# MSS_SPI register map
Vendor: Texas Instruments
Registers are 32-bit, access per field, no defined reset value unless marked. A register's access mark holds for its fields unless they carry their own. Offsets are as the file gives them; [hi:lo] are bit positions; lines under a group give offsets from that group; {n}, {i} and the like mark numbered series.

## MSS_SPI (part 2 of 3)
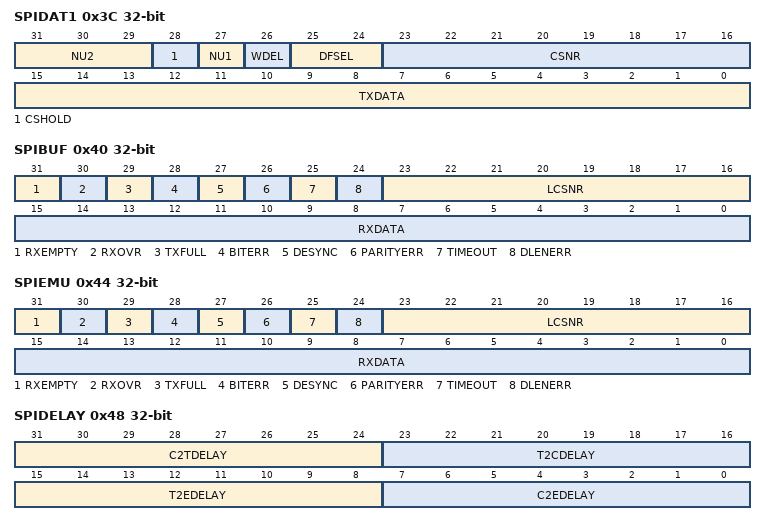
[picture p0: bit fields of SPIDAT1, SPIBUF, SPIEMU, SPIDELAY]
0x3C SPIDAT1 — SPI / MibSPI Transmit Data Register 1 When this register is read, contents of internal buffer register TXBUF which holds the latest written data will be returned.
  [31:29] NU2 ro — Reserved. Reads return ‘0’ and writes have no effect.
  [28] CSHOLD rw — Chip select hold mode. In SPI or compatibility mode MibSPI, the CSHOLD bit is supported in master mode only. In slave mode, this bit is ignored. CSHOLD defines the behavior of the chip select line at the end of a data transfer. 1 =The chip select signal is held active at the end of a transfer until a control field with new data and control information is loaded into SPIDAT1. If the new chip select information equals the previous one, the active chip select signal is extended until the end of transfer with CSHOLD cleared or until the chip select information changes. 0 =The chip select signal is deactivated at the end of a transfer after the T2CDELAY time has passed. If two consecutive transfers are dedicated to the same chip select this chip select signal will be deactivated for atleast 2VCLK cycles before it is activated again.
  [27] NU1 ro — Reserved. Reads return ‘0’ and writes have no effect.
  [26] WDEL rw — Enable the delay counter at the end of the current transaction. WDELAY bit is supported in Master mode only. In Slave mode, this bit will be ignored. 1 = After a transaction, WDELAY of the corresponding data format will be loaded into the delay counter. No transaction will be performed until the WDELAY counter overflows. The SPISCS pins will be de-activated for atleast (WDELAY + 2) * VCLK_Period duration. 0 = No delay will be inserted. However, SPISCS pins will still be de-activated for atleast for 2VCLK cycles if CSHOLD = ‘0’. In SPI or Compatibility mode of MibSPI, the duration for which the SPISCS pin remaining de-activated will also depend upon time taken to supply a new data after completing the shifting operation. If the internal buffer - TXBUF is already full, then the SPISCS will be deasserted for atleast 2 VCLK cycles(if WDEL = ‘0’).
  [25:24] DFSEL rw — DFSEL1 DFSEL0 Description 0 0 Data word format 0 is selected 0 1 Data word format 1 is selected 1 0 Data word format 2 is selected 1 1 Data word format 3 is selected
  [23:16] CSNR rw — Chip select number. CSNR defines the chip select that shall be activated during the data transfer. The value of CSNR[7:0] will be driven on SPISCS[7:0] lines during the transfer. Note: Effect of NUM_CS_PINS generic on CSNR bits. Actual number of bits implemented in CSNR[7:0] will depend upon the NUM_CS_PINS generic set during synthesis. Unimplemented bits will be read-only and will read ‘0’ always. Note: Preselecting a Format Register. Writing to just the Control Field (using byte writes) does not initiate any SPI transfer in Master mode. This feature can be used to setup SPICLK Phase or Polarity before actually starting the transfer by just updating the DFSEL fields in the control field to select the required Phase/Polarity combination.
  [15:0] TXDATA rw — SPI / MibSPI Transmit Data. When written, these bits will be copied to the Shift Register if it is empty. If the Shift Register is not empty, the TXBUF will hold the written values. SPIEN must be set to 1 before this register can be written to. Writing a 0 to the SPIEN register forces the lower 16 bits of the SPIDAT1 register to 0x00. Write to this register ONLY when using the automatic Slave Chip Select feature. See section 3, Operation Modes, on page 14. A write to this register will drive the contents of CSNR[7:0] into the respective pins in SPISCS[7:0] if those are configured as functional pins. When this register is read, contents of internal buffer register TXBUF which holds the latest written data will be returned. Irrespective of the character length, the Transmit data should be right justified before writing to SPIDAT1 register.
0x40 SPIBUF access not given — SPI / MibSPI Receive Buffer Register
  [31] RXEMPTY — Receive data buffer empty. When host reads the SPIBUF field or the whole SPIBUF register this will automatically set the RXEMPTY flag. When a data transfer is completed, the received data is copied into SPIBUF, the RXEMPTY flag is cleared. 1 =No data received since last reading of SPIBUF register. 0 =A new Data is received and copied into SPIBUF field. This flag gets set to ‘1’ under following conditions: oReading RXDATA portion of the SPIBUF register. oWriting ‘1’ to clear the RXINTFLG bit in SPIFLG register. Write-Clearing the RXINTFLG bit before reading the SPIBUF indicates the received data is being ignored. Conversely, RXINTFLG can be cleared by reading the RXDATA portion of the SPIBUF register. So, reading the full of SPIBUF register itself clears the Receiver Full Interrupt Flag.
  [30] RXOVR — Receive data buffer overrun. When a data transfer is completed and the received data is copied into the RXBUF while it is already full, RXOVR is set. Refer to Figure 1 for a view of internal logic diagram. An Overrun always occurs to the RXBUF, and SPIBUF contents never get Overwritten until after it is read by the VBUSP Master. If enabled, RXOVRN interrupt gets generated when RXBUF is Overwritten, and reading SPIFLG or SPIVECTx register shows the RXOVRN condition. However, two read operations to the SPIBUF register are required to reach the Overrun buffer. 1 =A receive data overrun condition occurred since last time reading the data field. 0 =No receive data overrun condition occurred since last time reading the data field. This bit is cleared to ‘0’ under the following conditions: o RXDATA portion of the SPIBUF register is read. o OVRNINTFLG bit in SPIFLG register is write-cleared. When an Overrun occurs, the SPIBUF contents will not be overwritten. Only the RXBUF contents are overwritten. When the SPIBUF is read out , the RXBUF contents get copied to the SPIBUF if RXBUF is full. So, the first data read out will be intact when an Overrun occurs. Note: A special condition under which RXOVR flag gets set. If both SPIBUF & RXBUF are already full and while another buffer receive is underway, if any errors like TIMEOUT, BITERR & DLEN_ERR occur, then RXOVR in RXBUF & SPIFLG registers will be set to indicate that the status flags are getting overwritten by the new transfer. This overrun should be treated like a normal Receiver Overrun.
  [29] TXFULL ro — Transmit data buffer full. This flag is a read-only flag. Writing into SPIDAT0 or SPIDAT1 field while TX Shift Register is full will automatically set the TXFULL flag. Once the data is copied to the Shift Register the TXFULL flag will be cleared. Writing to SPIDAT0/SPIDAT1 register when both TXBUF & the TX Shift Register are empty does not set the TXFULL flag. 1 =Transmit buffer is full, SPIDAT0/SPIDAT1 is not ready to accept a new data. 0 =Transmit buffer is empty, SPIDAT0/SPIDAT1 is ready to accept a new data.
  [28] BITERR — Mismatch of internal transmit data and transmitted data. 1 =A bit error occurred. The SPI / MibSPI samples the signal of the transmit pin (master: SIMO, slave: SOMI) at the receive point (half clock cycle after transmit point). If the sampled value differs from the transmitted value a bit error is detected and the flag BITERR is set. A possible reason for a bit error can be noise, a to high bit rate / capacitive load or another master/slave trying to transmit at the same time. 0 =No bit error occurred. This flag is cleared to ‘0’ when RXDATA portion of the SPIBUF register is read.
  [27] DESYNC — De-synchronization of slave device. De-synchronization monitor is active in master mode only. 1 =A slave device is de-synchronized. The master monitors the ENA signal coming from the slave device and sets the DESYNC flag if ENA is deactivated before the last reception point or after the last bit is transmitted plus tT2EDELAY (see Section 8.21). If DESYNCENA is set an interrupt is asserted. De-synchronization can occur if a slave device misses a clock edge coming from the master. 0 =No slave de-synchronization detected. This bit is valid in Master mode only. This flag is cleared to ‘0’ when RXDATA portion of the SPIBUF register is read. Note: Possible inconsistency of Desync flag in SPI/Compatibility mode MibSPI Due to the nature of this Error, under some circumstances it is possible for Desync error detected for the previous buffer to be visible in the current buffer. This is due to the fact that Receive Completion flag/interrupt will be generated when the buffer transfer is completed. But Desync will be detected after the buffer transfer is completed. So, if VBUS master reads the received data quickly when an RXINT is detected, then the status flag may not reflect the correct Desync condition. This inconsistency in Desync flag is valid only in SPI or Compatibility mode of MibSPI. In Multibuffer mode, Desync flag is always guaranteed to be for the current buffer.
  [26] PARITYERR — Calculated parity differs from received parity bit. 1 =A parity error occurred. If the parity generator is enabled (can be selected individually for each buffer) an even or odd parity bit is added at the end of a data word (see Section 8.23). During reception of the data word the parity generator calculates the reference parity and compares it to the received parity bit. In the event of a mismatch the PARITYERR flag is set. 0 =No parity error detected. This flag is cleared to ‘0’ when RXDATA portion of the SPIBUF register is read.
  [25] TIMEOUT — Time-out due to non-activation of ENA pin. 1 =An ENA signal time-out occurred. The SPI / MibSPI generates a time-out because the slave hasn’t responded in time by activating the ENA signal after the chip select signal has been activated. If a time-out condition is detected the corresponding chip select is deactivated immediately and the TIMEOUT flag is set. In addition the TIMOUT flag in the status field of the corresponding buffer and in the SPIFLG register is set. 0 =No ENA-pin time-out occurred. This flag is cleared to ‘0’ when RXDATA portion of the SPIBUF register is read. This bit is valid in Master mode only.
  [24] DLENERR — Data Length Error flag. 1 = A Data Length Error has occured. 0 = No Data Length Error has occured. This flag is cleared to ‘0’ when RXDATA portion of the SPIBUF register is read.
  [23:16] LCSNR ro — Last Chip select number. LCSNR in the status field is a copy of CSNR in the corresponding control field. It defines the chip select that has been activated during the last data transfer from the corresponding buffer. This is the copy of CSNR bits from SPIDAT1 latched at the end of a transfer. Note: Effect of NUM_CS_PINS generic on LCSNR bits. Actual number of bits implemented in LCSNR[7:0] will depend upon the NUM_CS_PINS generic set during synthesis. Unimplemented bits will read ‘0’ always
  [15:0] RXDATA ro — SPI Receive Data. This is the received data, transferred from the Receive Shift-Register at the end of a transfer completion. Irrespective of the programmed character length & the direction of shifting, the received data is stored right-justified in the register.
0x44 SPIEMU ro — SPI / MibSPI Emulation Register Note: All the fields ot SPIEMU register are Read-Only. Read operation on this register under any mode will not have any impact on the status of this or any other registers.
  [31] RXEMPTY — Receive data buffer empty. 1 = No data received since last reading of SPIBUF register. 0 = A new Data is received and copied into SPIBUF field.
  [30] RXOVR — Receive data buffer overrun. 1 =A receive data overrun condition occurred since last time reading the data field. 0 =No receive data overrun condition occurred since last time reading the data field.
  [29] TXFULL — Transmit data buffer full. 1 =Transmit buffer is full, SPIDAT0/SPIDAT1 is not ready to accept a new data. 0 =Transmit buffer is empty, SPIDAT0/SPIDAT1 is ready to accept a new data.
  [28] BITERR — Mismatch of internal transmit data and transmitted data. 1 =A bit error occurred. The SPI / MibSPI samples the signal of the transmit pin (master: SIMO, slave: SOMI) at the receive point (half clock cycle after transmit point). If the sampled value differs from the transmitted value a bit error is detected and the flag BITERR is set. A possible reason for a bit error can be noise, a to high bit rate / capacitive load or another master/slave trying to transmit at the same time. 0 =No bit error occurred.
  [27] DESYNC — De-synchronization of slave device. De-synchronization monitor is active in master mode only. 1 =A slave device is de-synchronized. The master monitors the ENA signal coming from the slave device and sets the DESYNC flag if ENA is deactivated before the last reception point or after the last bit is transmitted plus tT2EDELAY (see Section 8.21). If DESYNCENA is set an interrupt is asserted. De-synchronization can occur if a slave device misses a clock edge coming from the master. 0 =No slave de-synchronization detected. This bit is valid in Master mode only.
  [26] PARITYERR — Calculated parity differs from received parity bit. 1 =A parity error occurred. If the parity generator is enabled (can be selected individually for each buffer) an even or odd parity bit is added at the end of a data word (see Section 8.23). During reception of the data word the parity generator calculates the reference parity and compares it to the received parity bit. In the event of a mismatch the PARITYERR flag is set. 0 =No parity error detected.
  [25] TIMEOUT — Time-out due to non-activation of ENA pin. 1 =An ENA signal time-out occurred. The SPI / MibSPI generates a time-out because the slave hasn’t responded in time by activating the ENA signal after the chip select signal has been activated. If a time-out condition is detected the corresponding chip select is deactivated immediately and the TIMEOUT flag is set. In addition the TIMOUT flag in the status field of the corresponding buffer and in the SPIFLG register is set. 0 =No ENA-pin time-out occurred. This bit is valid in Master mode only.
  [24] DLENERR — Data Length Error flag. 1 = A Data Length Error has occured. 0 = No Data Length Error has occured.
  [23:16] LCSNR — Last Chip select number. LCSNR in the status field is a copy of CSNR in the corresponding control field. It defines the chip select that has been activated during the last data transfer from the corresponding buffer. This is the copy of CSNR bits from SPIDAT1 latched at the end of a transfer. Note: Effect of NUM_CS_PINS generic on LCSNR bits. Actual number of bits implemented in LCSNR[7:0] will depend upon the NUM_CS_PINS generic set during synthesis. Unimplemented bits will read ‘0’ always.
  [15:0] RXDATA — SPI Receive Data. SPI / MibSPI emulation is a mirror of the SPIBUF register. The only difference between SPIEMU and SPIBUF is that a read from SPIEMU does not clear any of the status flags.
0x48 SPIDELAY rw — SPI / MibSPI Delay Register
  [31:24] C2TDELAY — Chip-select-active-to-transmit-start-delay. C2TDELAY is used in master mode only. It defines a setup time for the slave device that delays the data transmission from the chip select active edge by a multiple of VBUSPCLK cycles. ChipSelect-active-to-transmission delays between 2 to 257 VBUSPCLK cycles can be achieved. If Phase = ‘1’, the delay between SCS fall-edge to the first edge of SPICLK will have an additional 0.5 SPICLK Period delay. This delay is as per the SPI protocol.
  [23:16] T2CDELAY — Transmit-end-to-chip-select-inactive-delay. T2CDELAY is used in master mode only. It defines a hold time for the slave device that delays the chip select deactivation by a multiple of VBUSPCLK cycles after the last bit is transferred. T2CDELAY can be configured between 2 and 256 VBUSPCLK cycles. If Phase = ‘0’, then between the last edge of SPICLK and rise-edge of SCS, there will be an additional delay of 0.5 SPICLK period. This is as per the SPI protocol Both C2TDELAY and T2CDELAY counters do not have any dependancy on SPIENA pin value. Even if the SPIENA pin is asserted by the Slave, Master will continue to delay the start of SPICLK until the C2TDELAY counter overflows. Similarly, even if the SPIENA pin is deasserted by the Slave, Master will continue to hold the SPISCS pins active until the T2CDELAY counter overflows. This way, it is guaranteed that the setup/hold times of the SPISCS pins is determined by the Delay timers alone. To achieve better throughput, it should be ensured that these two timers are kept at the minimum possible values.
  [15:8] T2EDELAY — Transmit-data-finished-to-ENA-pin-inactive-time-out. T2EDELAY is used in master mode only. It defines a time-out value as a multiple of SPI clock before the ENAble signal has to become inactive and after the CS becomes inactive. The SPI clock depends on which data format is selected. If the slave device is missing one or more clock edges, it is becoming de-synchronized. Although the master has finished the data transfer the slave is still waiting for the missed clock pulses and the ENA signal isn’t disabled. The T2EDELAY defines a time-out value that triggers the DESYNC flag, if the ENA signal isn’t deactivated in time. DESYNC flag is set to indicate that the Slave device did not deassert its SPIENA pin in time to acknowledge that it has received all the bits of the sent character. If T2CDELAY is programmed a non-zero value, then T2EDELAY will start only after the T2CDELAY completes. This should be taken into consideration to determine an optimum value of T2EDELAY. Note: Zero T2EDELAY If T2EDELAY is not programmed or programmed to ‘0’, then the Master SPI/MibSPI does not wait for SPIENA pin to be deasserted. It ignores the state of the SPIENA pin after the transmission is completed.
  [7:0] C2EDELAY — Chip-select-active-to-ENA-signal-active-time-out C2EDELAY is utilized only in master mode and it applies only if the addressed slave generates an ENA signal as a hardware handshake response. C2EDELAY defines the maximum time between the SPI / MibSPI activating the chip select signal and the addressed slave responding by activating the ENA signal. C2EDELAY defines a time-out value as a multiple of SPI clocks. The SPI clock depends on whether data format 0 or data format 1 is selected. If the slave device is not responding with the ENA signal before the time-out value is reached, the TIMEOUT flag in SPIFLG register is set and an interrupt is asserted if enabled. If a time-out occurs the MibSPI clears the transmit request of the timed-out buffer, sets the TIMEOUT flag for the current buffer and continues with the transfer of the next buffer in the sequence that is enabled. If C2TDELAY is programmed a non-zero value, then C2EDELAY will start only after the C2TDELAY completes. This should be taken into consideration to determine an optimum value of C2EDELAY. Note: Zero C2EDELAY If C2EDELAY is not programmed or programmed to ‘0’, then the Master SPI/MibSPI waits until the SPIENA pin to asserted before it can start the transfer. If the SPIENA pin is not asserted due to a malfunctioning Slave, the Master will wait forever. This might cause hang-up situation. it is recommended to program to C2EDELAY to a suitable value whenever SPIENA pin is used as functional.
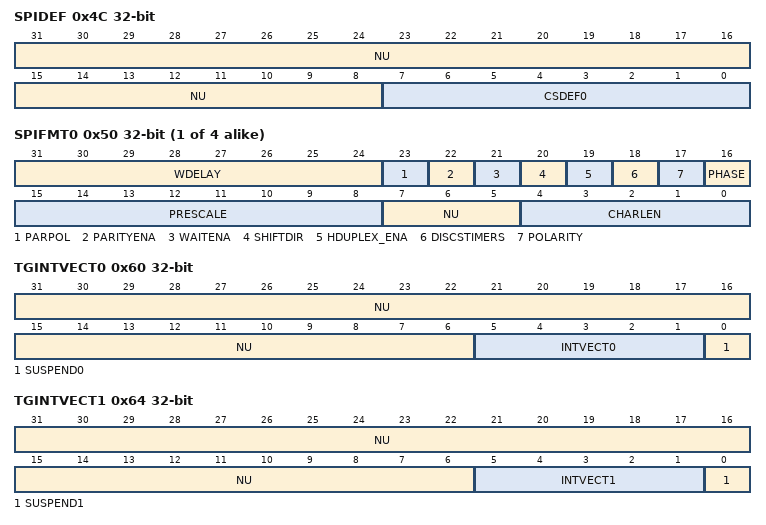
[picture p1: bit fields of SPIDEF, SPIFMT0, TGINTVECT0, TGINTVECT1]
0x4C SPIDEF — SPI / MibSPI Default Chip select Register
  [31:8] NU ro — Reserved. Reads return ‘0’ and writes have no effect.
  [7:0] CSDEF0 rw — Chip select default pattern. Master mode behavior. The CSDEFx bits are output to the chip select pins when no transmission are currently performed. It allows the user to set a chip select pattern which deselects all the SPI slaves. 1 =If CSDEFx is set to “1” the corresponding chip select is set to “1” while SPI/MibSPI is IDLE. 0 =If CSDEFx is set to “0” the corresponding chip select is set to “0” while SPI/MibSPI is IDLE. Note: Effect of NUM_CS_PINS generic on CSDEF bits. Actual number of bits implemented in CSDEF[7:0] will depend upon the NUM_CS_PINS generic set during synthesis. Unimplemented bits will be treated as reserved, read-only and will read ‘0’ always.
{0x50+4i} SPIFMT{i} (i=0..3) — SPI / MibSPI Data Format Register {i}
  [31:24] WDELAY rw — Delay in between transmissions for data format x (x= 0,1,2,3). Idle time that will be applied at the end of the current transmission if the bit WDEL is set in the current buffer. The delay to be applied is equal to: WDELAY * PVBUSPCLK + 2 * PVBUSPCLK. PVBUSPCLK -> Period of VBUSPCLK.
  [23] PARPOL rw — Parity polarity: even or odd. PARPOLx can be modified in privilege mode only. It can be used for data format x (x= 0,1,2,3). 1 =An odd parity flag is added at the end of the transmit data stream. 0 =An even parity flag is added at the end of the transmit data stream.
  [22] PARITYENA rw — Parity enable for data format x. 1= A parity is transmitted at the end of each transmit data stream. At the end of a transfer the parity generator compares the received parity bit with the locally calculated parity flag. If the parity bits do not match the RXERR flag is set in the corresponding control field. The parity type (even or odd) can be selected via the PARPOL bit. 0= No parity generation/ verification is performed for this data format. If an Uncorrectable Error Flag is set in a Slave mode MibSPI, then wrong parity bit will be transmitted to indicate to the master that there has been some issue with the data parity. The SOMI pin will be forced to transmit all ‘0’s. And parity bit will be transmitted as ‘1’ if even parity is selected and as ‘0’ if odd parity is selected(using the PARPOLx bit of this register). This behavior will be irrespective of an UPE on either TXRAM or RXRAM.
  [21] WAITENA rw — Master waits for ENA signal from slave for data format x. WAITENA is considered in master mode only. In slave mode this bit has no meaning. WAITENA enables a flexible SPI network where slaves with ENA signal and slaves without ENA signal can be mixed. WAITENA defines for each buffer whether the addressed slave generates the ENA signal or does not. 1= Before the SPI / MibSPI starts the data transfer it waits for the ENA signal to become low. If the ENA signal is not pulled down by the addressed slave before the internal time-out counter (C2EDELAY) overflows, then the Master aborts the transfer and sets the TIMEOUT error flag. 0= The SPI / MibSPI does not wait for the ENA signal from the slaves and directly starts the transfer.
  [20] SHIFTDIR rw — Shift direction for data format x. With bit SHIFTDIRx the shift direction for data format x (x=0,1,2,3) can be selected. 1 =Data format x shift direction: Least significant bit is shifted out first. 0 =Data format x shift direction: Most significant bit is shifted out first.
  [19] HDUPLEX_ENA rw — Half Duplex transfer mode enable for Data Format x. This bit controls the I/O function of SOMI/SIMO lines for a specific requirement where in the case of Master mode, TX pin - SIMO will act as an RX pin, and in the case of Slave mode, RX pin - SIMO will act as a TX pin. 0 = Normal Full Duplex transfer. 1 = If MASTER = ‘1’, SIMO pin will act as an RX pin (No TX possible) If MASTER = ‘0’, SIMO pin will act as a TX pin (No RX possible). For all normal operations, HDUPLEX_ENAx bits should always remain ‘0’. It is intended for the usage when the SIMO pin is used for both TX & RX operations at different times.
  [18] DISCSTIMERS rw — Disable Chipselect Timers for this format register. The C2TDELAY & T2CDELAY timers are by default enabled for all the Data Format registers. Using this bit, these timers can be disabled for particular Data Format if not required. When a Master is handling multiple Slaves, with varied set-up hold requirement, the application can selectively choose to include or not include the ChipSelect Delay timers for any Slaves. 0 = Both C2TDELAY & T2CDELAY counts are inserted for the ChipSelects. 1 = No C2TDELAY or T2CDELAY is inserted in the ChipSelect timings.
  [17] POLARITY rw — SPI data format x clock polarity. POLARITYx defines the clock polarity of data format x. POLARITYx can be modified in privilege mode only. 1 =If POLARITYx is set to “1” the SPI clock signal is high-inactive, i.e. before and after data transfer the clock signal is high. 0 =If POLARITYx is set to “0” the SPI clock signal is low-inactive, i.e. before and after data transfer the clock signal is low.
  [16] PHASE rw — SPI Data format x clock delay. PHASEx defines the clock delay of data format x. PHASEx can be modified in privilege mode only. 1 =If PHASEx is set to “1” the SPI clock signal is delayed by a half SPI clock cycle versus the transmit / receive data stream. The first transmit bit has to output prior to the first clock edge. Master and slave receive the first bit with the first edge 0 =If PHASEx is set to “0” the SPI clock signal is not delayed versus the transmit / receive data stream. The first data bit is transmitted with the first clock edge and the first bit is received with the second (inverse) clock edge Note: Restriction on SPICLK Phase/Polarity change in Slave Mode In Slave mode if Phase and/or Polarity of SPICLK has to be changed, the following sequence should be used. oClear the GCR1.SPIEN bit to ‘0’. oSet the required Phase/Polarity values in SPIFMTx registers. oSet the GCR1.SPIEN bit back to ‘1’. The setting of GCR1.SPIEN bit in Slave SPI/MibSPI to ‘1’ should be done only after the Polarity of the incoming SPICLK signal changes (if POLARITYx bit was changed in the configuration).
  [15:8] PRESCALE rw — SPI data format x prescaler. PRESCALEx can be modified in privilege mode only. PRESCALEx determines the bit transfer rate of data format x if the SPI is the network master. PRESCALEx is directly derived from VBUSPCLK. If the SPI / MibSPI is configured as slave, PRESCALEx DOES NOT NEED to be configured. The clock rate for data format x can be calculated as BRFormat = VBUSPCLCK/(PRESCALEx+1) When PRESCALEx is set to zero (0), the SPI clock rate defaults to VBUSPCLK/2. Any write to this field will update EPRESCALE_FMTx field of EPRESCALEy (y=1,2) registers with EPRESCALE_FMTx(11:8) bits rounded off to ‘000’. Any write to EPRESCALE_FMTx field of the EXTENDED_PRESCALEy (y=1,2) register will cause its lower 8bits to be reflected in this field as well.
  [7:5] NU ro — Reserved. Reads return ‘0’ and writes have no effect.
  [4:0] CHARLEN rw — SPI data format x data word length. CHARLENx defines the word length of data format x. Legal values are 0x02 (data word length = 2 bit) to 0x10 (data word length = 16). Illegal values, such as 0x00 or 0x1F are not detected and their effect is indeterminate.
0x60 TGINTVECT0 ro — SPI Interrupt Vector Register 0 / MibSPI Transfer Group Interrupt Vector Register 0
  [31:6] NU — Reserved. Reads return ‘0’ and writes have no effect.
  [5:1] INTVECT0 — Interrupt vector for interrupt line INT0. INTVECT0 returns the vector of the pending interrupt at interrupt line INT0. If more than one interrupts are pending, INTVECT0 always references the highest priority interrupt source first. The vectors generated are different for SPI / Compatibility mode of MibSPI and Multibuffer mode of MibSPI. INTVECT0 field just reflects the status of SPIFLG register in a vectorized format. So, any updates to SPIFLG will automatically reflect in the Vector value in this register. SPI / Compatibility mode - MibSPI The interrupts available for SPI or Compatibility mode - MibSPI, in the descending order of their priorities are as given below. Transmission Error Interrupt Receive Buffer Overrun Interrupt Receive Buffer Full Interrupt Transmit Buffer Empty Interrupt Vectors for each of these interrupts will be reflected on the INTVECT0 bits, when they occur. Reading the vectors for the “Receive Buffer Overrun” & “Receive Buffer Full” interrupts will automatically clear the respective flags in the SPIFLG register. On reading the INTVECT0 bits, the vector of the next highest priority interrupt (if any) will be then reflected on the INTVECT0 bits. If two or more interrupts occur simultaneously, the vector for the higest priority interrupt will be reflected on the INTVECT0 bits. Reading the Vector register when “Transmitter Empty” is indicated does not clear the TXINTFLG in SPIFLG register. Writing a new data to SPIDATx register clears the “Transmitter Empty” interrupt. INTVECT0[4:0] Description 00000b no interrupt pending 10001b Error interrupt pending. Refer to Least Significant (LS) Byte of SPIFLG to determine more details about the type of error. 10011b Pending interrupt is “Receive Buffer Overrun Interrupt” 10010b Pending interrupt is “Receive Buffer Full Interrupt” 10100b Pending interrupt is “Transmit Buffer Empty Interrupt” All other bit combinations Reserved Note: Exception for clearing of RXINT If both SPIBUF and RXBUF (internal buffer) are full, then, reading TGINTVECT0 register (while it shows 10010) does not clear the RXINTFLG in SPIFLG register. In this case, only way to clear the Interrupt is to read the SPIBUF again until there’s no more unread RX data.
  [0] SUSPEND0 — “Transfer suspended” or “transfer finished” interrupt.(MibSPI only) The SUSPEND0 flag is updated depending on the type of interrupt reflected by the VECTOR value field. 1 =The interrupt type is a “transfer suspended” interrupt. I.e. the transfer group referenced by INTVECT0 has asserted an interrupt, because the buffer to be transferred next is in “suspend to wait” mode. 0 =The interrupt type is a “transfer finished” interrupt. I.e. the buffer array referenced by INTVECT0 has asserted an interrupt, because all of the data from the whole transfer group has been transferred. Note: Special case for SUSPEND interrupt When there’s a “transfer suspended” interrupt (SUSPEND0 bit is set to ‘1’), reading the TGINTVECT0 register does not clear the “TG Suspended” interrupt. The SUSPEND condition should be resolved first before the interrupt can be cleared. The SUSPEND condition can be cleared by writing a new data to that TXRAM location and/or reading the data from that RXRAM location depending upon the SUSPEND criteria programmed in the “BUFMODE” field of that TXRAM location. The SUSPEND0 bit always returns value ‘0’ in SPI / Compatibility mode MibSPI. When there is an RXOVRN or any Error interrupt in Multibuffer mode, SUSPEND0 bit stays ‘0’. Refer to Section 6.2 on page 77 & Section 6.3 on page 77 for more details and notes on better handling of interrupts. Note: Reading Error Vector Reading an Error Vector in the TGINTVECT0 register will NOT clear the Error flags in the SPIFLG register. The Error Flags in SPIFLG need to be write-cleared after servicing them suitably. If “TG Completed” interrupt occurs for a TG and after a while “TG Suspended” flag too gets set for the same TG, then the TGINTVECT0 register will show “TG Completed” interrupt giving it higher priority than the “TG Suspended” interrrupt.
0x64 TGINTVECT1 ro — SPI Interrupt Vector Register 1 / MibSPI Transfer Group Interrupt Vector Register 1
  [31:6] NU — Reserved. Reads return ‘0’ and writes have no effect.
  [5:1] INTVECT1 — Interrupt vector for interrupt line INT1. INTVECT1 returns the vector of the pending interrupt at interrupt line INT0. If more than one interrupt is pending, INTVECT1 always references the highest priority interrupt source first. The vectors generated are different for SPI / Compatibility mode of MibSPI and Multibuffer mode of MibSPI. INTVECT1 field just reflects the status of SPIFLG register in a vectorized format. So, any updates to SPIFLG will automatically reflect in the Vector value in this register. SPI / Compatibility mode - MibSPI The interrupts available for SPI / Compatibility mode - MibSPI, in the descending order of their priorities are as given below. Transmission Error Interrupt Receive Buffer Overrun Interrupt Receive Buffer Full Interrupt Transmit Buffer Empty Interrupt Vectors for each of these interrupts will be reflected on the INTVECT1 bits, when they occur. Reading the vectors for the “Receive Buffer Overrun” & “Receive Buffer Full” interrupts will automatically clear the respective flags in the SPIFLG register. On reading the INTVECT1 bits, the vector of the next highest priority interrupt (if any) will then be reflected on the INTVECT1 bits. If two or more interrupts occur simultaneously, the vector for the higest priority interrupt will be reflected on the INTVECT1 bits. Reading the Vector register when “Transmitter Empty” is indicated does not clear the TXINTFLG in SPIFLG register. Writing a new data to SPIDATx register clears the “Transmitter Empty” interrupt. 00000b no interrupt pending 10001b Error interrupt pending. Refer to LS Byte of SPIFLG to determine more details about the type of error. 10011b Pending interrupt is “Receive Buffer Overrun Interrupt” 10010b Pending interrupt is “Receive Buiffer Full Interrupt” 10100b Pending interrupt is “Transmit Buffer Empty Interrupt” All other bit combinations Reserved Note: Exception for clearing of RXINT If both SPIBUF and RXBUF (internal buffer) are full, then, reading TGINTVECT1 register (while it shows 10010) does not clear the RXINTFLG in SPIFLG register. In this case, only way to clear the Interrupt is to read out the SPIBUF again until there’s no more unread RX data.
  [0] SUSPEND1 — “Transfer suspended” or “transfer finished” interrupt.(MibSPI Only) The SUSPEND1 flag is updated depending on the type of interrupt reflected by the VECTOR value field. 1 =The interrupt type is a “transfer suspended” interrupt. I.e. the transfer group referenced by INTVECT1 has asserted an interrupt, because the buffer to be transferred next is in “suspend to wait” mode. 0 =The interrupt type is a “transfer finished” interrupt. I.e. the buffer array referenced by INTVECT1 has asserted an interrupt, because all data from the whole transfer group has been transferred. Note: Special case for SUSPEND interrupt When there’s a “transfer suspended” interrupt(SUSPEND1 bit is set to ‘1’), reading the TGINTVECT1 register does not clear the “TG Suspended” interrupt. The SUSPEND condition should be resolved first before the interrupt can be cleared. This condition can be cleared by writing a new data to that TXRAM location and/or reading the data from that RXRAM location depending upon the SUSPEND criteria programmed in the “BUFMODE” field of that TXRAM location. The SUSPEND1 bit always returns value ‘0’ in SPI / Compatibility mode MibSPI. Even while there is an RXOVRN or any Error interrupt in Multibuffer mode, SUSPEND1 bit stays ‘0’. Refer to Section 6.2 on page 77 & Section 6.3 on page 77 for more details and notes on better handling of interrupts. Note: Reading Error Vector Reading an Error Vector in the TGINTVECT1 register will NOT clear the Error flags in the SPIFLG register. The Error Flags in SPIFLG need to be write-cleared after servicing them suitably. If “TG Completed” interrupt occurs for a TG and after a while “TG Suspended” flag too gets set for the same TG, then the TGINTVECT1 register will show “TG Completed” interrupt giving it higher priority than the “TG Suspended” interrrupt.
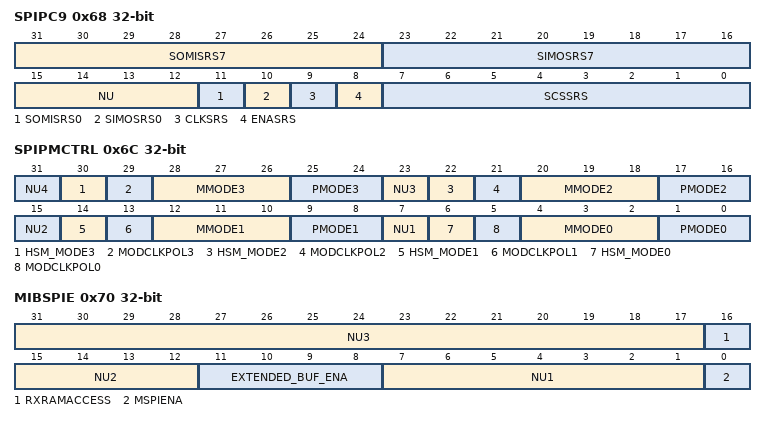
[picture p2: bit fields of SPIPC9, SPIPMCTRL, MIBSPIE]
0x68 SPIPC9 — SPI/MibSPI Pin Control Register 9 (SPIPC9) - SPISRSEL
  [31:24] SOMISRS7 rw — Each of these 7 bits controls the slew rate for the corresponding SPISOMIx pin. 0 =Normal Buffer Select. 1 =Slow Buffer Select.
  [23:16] SIMOSRS7 rw — Each of these 7 bits controls the slew rate for the corresponding SPISIMOx pin. 0 =Normal Buffer Select. 1 =Slow Buffer Select.
  [15:12] NU ro — Reserved. Reads return ‘0’ and writes have no effect.
  [11] SOMISRS0 rw — This bit controls the slew rate for SPISOMI0 pin. 0 =Normal Buffer Select. 1 =Slow Buffer Select. Note: Bit 11 or bit 24 can be used to control the slew rate for SPISOMI0. If a 32 bit write is performed, bit 11 will have priority over bit 24.
  [10] SIMOSRS0 rw — This bit controls the slew rate for SPISIMO0 pin. 0 =Normal Buffer Select. 1 =Slow Buffer Select. Note: Bit 10 or bit 16 can be used to control the slew rate for SPISIMO0. If a 32 bit write is performed, bit 10 will have priority over bit 16.
  [9] CLKSRS rw — This bit controls the slew rate for SPICLK pin. 0 =Normal Buffer Select. 1 =Slow Buffer Select.
  [8] ENASRS rw — This bit controls the slew rate for SPIENA pin. 0 =Fast Buffer Select. 1 =Slow Buffer Select.
  [7:0] SCSSRS rw — Each of these 7 bits controls the slew rate for the corresponding SPISCSx pin. 0 =Normal Buffer Select. 1 =Slow Buffer Select. Note: Effect of NUM_CS_PINS generic on ChipSelect bits. Actual number of bits implemented in SCSSRS[7:0] will depend upon the NUM_CS_PINS generic set during synthesis. Unimplemented bits will be read-only and will read ‘0’ always.
0x6C SPIPMCTRL — SPI/MibSPI Parallel/Modulo Mode Control Register
  [8n-1] NU{n} ro (n=1..4) — Reserved. Reads return ‘0’ and writes have no effect.
  [30] HSM_MODE3 rw — High Speed Modulo Mode control bit for Data Format 3. Controls whether the PMODE3 bits will result in Modulo Format data transfer or not. Refer to Section 3.26 for details about the HSM Mode. 0 = Normal mode - Normal Parallel mode if PMODE3 bits are non-zero. 1 = High Speed Modulo Mode. Data transfer will happen in Modulo Format if PMODE3 bits are non-zero
  [29] MODCLKPOL3 rw — Modulo mode SPICLK Polarity for Data Format 3 Determines the Polarity of the SPICLK in Modulo mode only. If MODULO MODE[2:0] bits are “000”, this bit will be ignored. 0 = Normal SPICLK in all the modes. 1 = Polarity of the SPICLK will be inverted if Modulo mode is selected
  [28:26] MMODE3 rw — These bits determine whether the SPI/MibSPI operates with 1, 2, 4, 5, or 6 data lines (if Modulo Option is supported by the module) for Data Format 3.000 = Normal single dataline mode - Default (PMODE should be set to “00”) 001 = 2-data line Mode (PMODE should be set to “00”) 010 = 3-data line mode (PMODE should be set to “00”) 011 = 4-data line mode (PMODE should be set to “00”) 100 = 5-data line mode (PMODE should be set to “00”) 101 = 6-data line mode (PMODE should be set to “01”) 110 = Reserved 111 = Reserved
  [25:24] PMODE3 rw — Parallel mode bits determine whether the SPI/MibSPI operates with 1, 2 ,4 or 8 data lines for Data Format 3. 00 = normal operation / 1-data line (MMODE should be set to “000”) 01 = 2-data line mode (MMODE should be set to “000”) 10 = 4-data line mode (MMODE should be set to “000”) 11 = 8-data line mode (MMODE should be set to “000”)
  [22] HSM_MODE2 rw — High Speed Modulo Mode control bit for Data Format 2. Controls whether the PMODE2 bits will result in Modulo Format data transfer or not. Refer to Section 3.26 for details about the HSM Mode. 0 = Normal mode - Normal Parallel mode if PMODE2 bits are non-zero. 1 = High Speed Modulo Mode. Data transfer will happen in Modulo Format if PMODE2 bits are non-zero
  [21] MODCLKPOL2 rw — Modulo mode SPICLK Polarity for Data Format 2. Determines the Polarity of the SPICLK in Modulo mode only. If MMODE[2:0] bits are “000”, this bit will be ignored. 0 = Normal SPICLK in all the modes. 1 = Polarity of the SPICLK will be inverted if Modulo mode is selected
  [20:18] MMODE2 rw — These bits determine whether the SPI/MibSPI operates with 1, 2, 4, 5, or 6 data lines (if Modulo Option is supported by the module) for Data Format 2. 000 = 1-data line Mode - Default (PMODE should be set to “00”) 001 = 2-data line Mode (PMODE should be set to “00”) 010 = 3-data line mode (PMODE should be set to “00”) 011 = 4-data line mode (PMODE should be set to “00”) 100 = 5-data line mode (PMODE should be set to “00”) 101 = 6-data line mode (PMODE should be set to “01”) 110 = Reserved 111 = Reserved
  [17:16] PMODE2 rw — Parallel mode bits determine whether the SPI/MibSPI operates with 1, 2 ,4 or 8 data lines for Data Format 2. 00 = normal operation / 1-data line (MMODE should be set to “000”) 01 = 2-data line mode (MMODE should be set to “000”)10 = 4-data line mode (MMODE should be set to “000”) 11 = 8-data line mode (MMODE should be set to “000”)
  [14] HSM_MODE1 rw — High Speed Modulo Mode control bit for Data Format 1. Controls whether the PMODE1 bits will result in Modulo Format data transfer or not. Refer to Section 3.26 for details about the HSM Mode. 0 = Normal mode - Normal Parallel mode if PMODE1 bits are non-zero. 1 = High Speed Modulo Mode. Data transfer will happen in Modulo Format if PMODE1 bits are non-zero.
  [13] MODCLKPOL1 rw — Modulo mode SPICLK Polarity for Data Format 1. Determines the Polarity of the SPICLK in Modulo mode only. If MMODE[2:0] bits are “000”, this bit will be ignored. 0 = Normal SPICLK in all the modes. 1 = Polarity of the SPICLK will be inverted if Modulo mode is selected.
  [12:10] MMODE1 rw — These bits determine whether the SPI/MibSPI operates with 1, 2, 4, 5, or 6 data lines (if Modulo Option is supported by the module) for Data Format 1. 000 = 1-data line Mode - Default (PMODE should be set to “00”) 001 = 2-data line Mode (PMODE should be set to “00”) 010 = 3-data line mode (PMODE should be set to “00”) 011 = 4-data line mode (PMODE should be set to “00”) 100 = 5-data line mode (PMODE should be set to “00”) 101 = 6-data line mode (PMODE should be set to “01”) 110 = Reserved 111 = Reserved
  [9:8] PMODE1 rw — Parallel mode bits determine whether the SPI/MibSPI operates with 1, 2 ,4 or 8 data lines for Data Format 1. 00 = normal operation / 1-data line (MMODE should be set to “000”) 01 = 2-data line mode (MMODE should be set to “000”) 10 = 4-data line mode (MMODE should be set to “000”) 11 = 8-data line mode (MMODE should be set to “000”)
  [6] HSM_MODE0 rw — High Speed Modulo Mode control bit for Data Format 0. Controls whether the PMODE0 bits will result in Modulo Format data transfer or not. Refer to Section 3.26 for details about the HSM Mode. 0 = Normal mode - Normal Parallel mode if PMODE0 bits are non-zero. 1 = High Speed Modulo Mode. Data transfer will happen in Modulo Format if PMODE0 bits are non-zero.
  [5] MODCLKPOL0 rw — Modulo mode SPICLK Polarity for Data Format 0. Determines the Polarity of the SPICLK in Modulo mode only. If MMODE[2:0] bits are “000”, this bit will be ignored. 0 = Normal SPICLK in all the modes. 1 = Polarity of the SPICLK will be inverted if Modulo mode is selected.
  [4:2] MMODE0 rw — These bits determine whether the SPI/MibSPI operates with 1, 2, 4, 5, or 6 data lines (if Modulo Option is supported by the module) for Data Format 0. 000 = 1-data line Mode - Default (PMODE should be set to “00”) 001 = 2-data line Mode (PMODE should be set to “00”) 010 = 3-data line mode (PMODE should be set to “00”) 011 = 4-data line mode (PMODE should be set to “00”) 100 = 5-data line mode (PMODE should be set to “00”) 101 = 6-data line mode (PMODE should be set to “01”) 110 = Reserved 111 = Reserved
  [1:0] PMODE0 rw — Parallel mode bits determine whether the SPI/MibSPI operates with 1, 2 ,4 or 8 data lines for Data Format 0. 00 = normal operation / 1-data line (MMODE should be set to “000”) 01 = 2-data line mode (MMODE should be set to “000”) 10 = 4-data line mode (MMODE should be set to “000”) 11 = 8-data line mode (MMODE should be set to “000”)
0x70 MIBSPIE — MibSPI Enable Register
  [31:17] NU3 ro — Reserved. Reads return ‘0’ and writes have no effect.
  [16] RXRAMACCESS rw — Receive RAM Access control Bit. During normal operating mode of MibSPI, the Receive Data/Status portion of Multibuffer RAM is read-only. To enable testing of Data Integrity checks of Receive RAM, a special read/write access control is provided through this bit. 0 = The RX portion of Multibuffer RAM is not writable by the CPU. That is, portion of Multibuffer RAM, addressed by an offset of 0x200-0x3FF is write protected. 1 = The whole of Multibuffer RAM is fully accessible for read/write by the CPU.
  [15:12] NU2 ro — Reserved.Reads return ‘0’ and writes have no effect
  [11:8] EXTENDED_BUF_ENA rw — Enables the support for 256 buffers. By default MibSPI supports up to 128 buffers for both TX and RX. It is also possible to extend the support to 256 buffers as a parameterized implementation. This field can be used to enable/disable the support for Extended Buffers. This Enable field is implemented only if “EXTENDED_BUF” parameter is set to ‘1’. If the parameter is set to ‘0’, this field is read-only and reads the disable value. Write (Privilege mode only) 1010 - Enable the Extended Buffer mode - up to 256 buffers can be used 0101 - Disable the Extended Buffer mode - MibSPI supports only 128 buffers All other values - writes are ignored and the values are not updated into this field. The state of the feature remains unchanged. Read (both privilege and user modes) 1010 - Extended Buffer mode is enabled - up to 256 buffers can be used 0101 - Extended Buffer mode is disabled - MibSPI supports only 128 buffers
  [7:1] NU1 ro — Reserved. Reads return ‘0’ and writes have no effect.
  [0] MSPIENA rw — Multibuffer mode Enable. After power-up or reset MSPIENA remains cleared, which means that the MibSPI runs in compatibility mode by default. If Multibuffer mode is desired, this register should be configured first after configuring the SPIGCR0 register. Unless MSPIENA is set to ‘1’, the Multibuffer mode registers are not writable. Refer to Section 3.3 for the grouping of registers into Compatibility mode and Multibuffer mode. 1 =The MibSPI is configured to run in MibSPI mode (Multibuffer mode). In this mode the additional features are available. 0 =The MibSPI runs in compatibility mode, i.e. in this mode the MibSPI is fully code compliant to the standard TMS470 Platform SPI. No Multibuffer feature is supported
